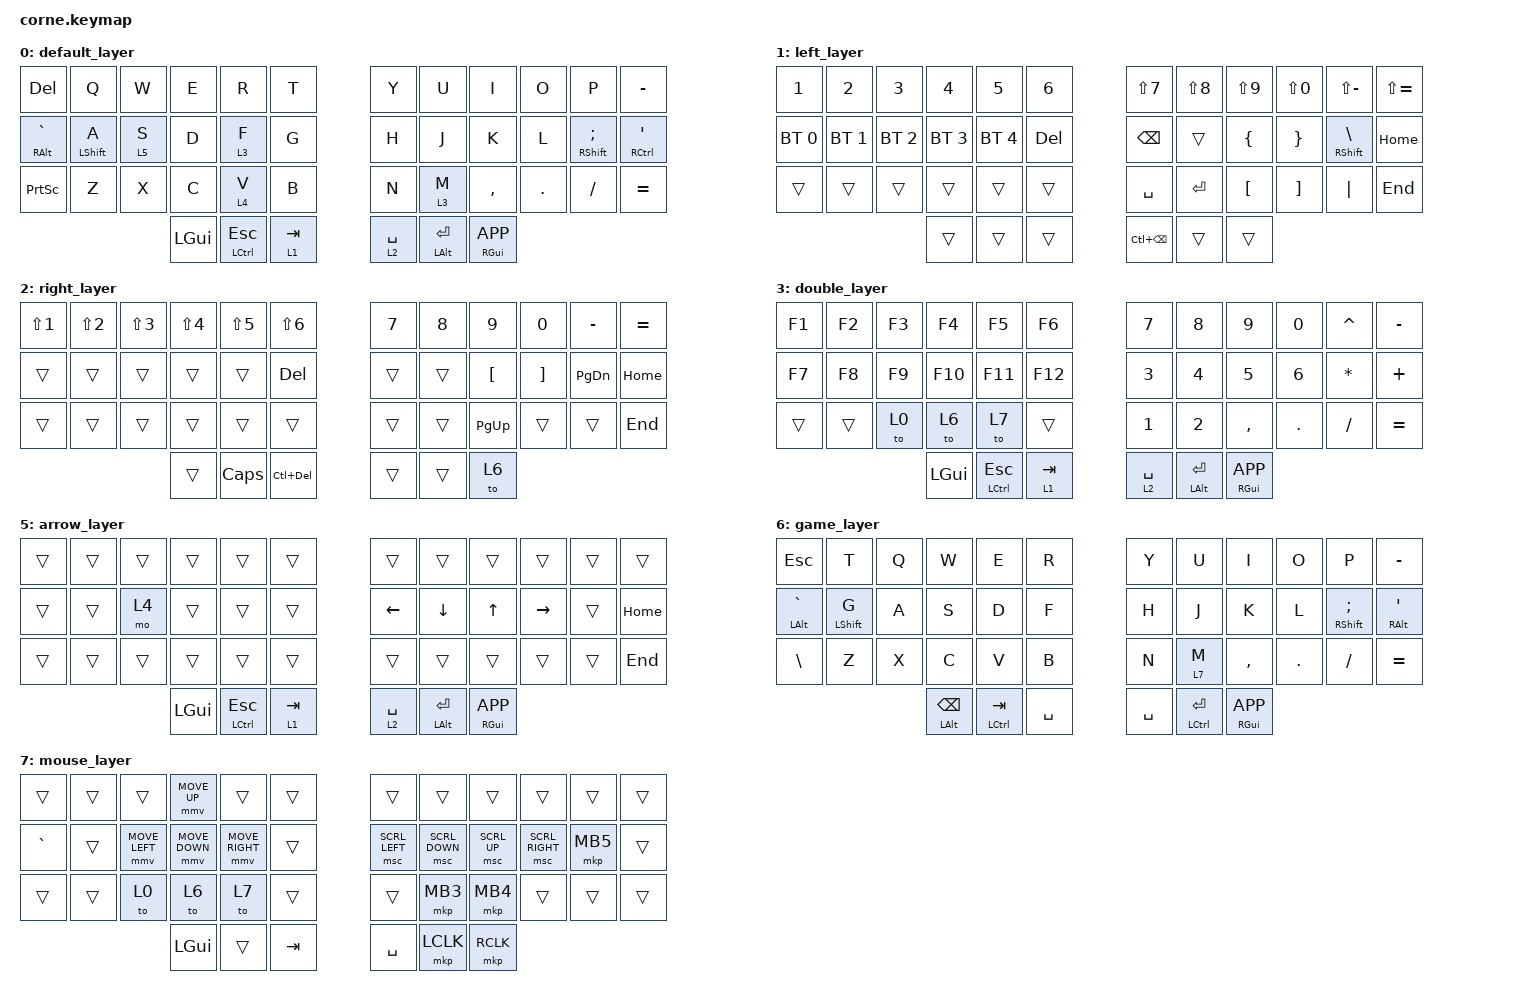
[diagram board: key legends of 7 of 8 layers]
/*
 * Copyright (c) 2020 The ZMK Contributors
 *
 * SPDX-License-Identifier: MIT
 */

#include <behaviors.dtsi>
#include <dt-bindings/zmk/keys.h>
#include <dt-bindings/zmk/bt.h>

// mouse
#include <dt-bindings/zmk/pointing.h>

&mt {
                        tapping-term-ms = <200>;
};

&lt {
            tapping-term-ms = <200>;    // <---[[moderate duration]]
            quick-tap-ms = <0>;
            flavor = "balanced";
};

/ {
    behaviors {
        hm: homerow_mods {
            compatible = "zmk,behavior-hold-tap";
            #binding-cells = <2>;
            tapping-term-ms = <150>;
            quick-tap-ms = <0>;
            flavor = "tap-preferred";
            bindings = <&kp>, <&kp>;
        };
    };
    behaviors {
        bhm: balanced_homerow_mods {
            compatible = "zmk,behavior-hold-tap";
            #binding-cells = <2>;
            tapping-term-ms = <200>;    // <---[[moderate duration]]
            quick-tap-ms = <0>;
            flavor = "balanced";
            bindings = <&kp>, <&kp>;
        };
    };

        keymap {
                compatible = "zmk,keymap";

                default_layer {
// -----------------------------------------------------------------------------------------
// |      |  Q  |  W  |  E  |  R  |  T  |   |  Y  |  U   |  I  |  O  |  P  |      |
// | CT/E |  A  |  S  |  D  |  F  |  G  |   |  H  |  J   |  K  |  L  |  ;  |  '   |
// | S/HM |  z  |  x  |  c  |  v  |  b  |   |  n  |  m   |  ,  |  .  |  /  | A/ED |
//                    | GUI | LWR | SPC |   | ENT | RSE  | ALT |
                        bindings = <
   &kp DEL       &kp Q        &kp W        &kp E              &kp R           &kp T         &kp Y &kp U  &kp I     &kp O     &kp P      &kp MINUS
   // &bhm LCTRL GRAVE     &bhm LSHFT A  &lt 5 S      &kp D            &lt 3 F         &kp G  &kp H &kp J  &kp K     &kp L     &bhm RSHFT SEMI &bhm RALT SQT
   &bhm RALT GRAVE     &bhm LSHFT A  &lt 5 S      &kp D            &lt 3 F         &kp G  &kp H &kp J  &kp K     &kp L     &bhm RSHFT SEMI &bhm RCTRL SQT
   &kp PSCRN   &kp Z   &kp X        &kp C              &lt 4 V           &kp B         &kp N &lt 3 M  &kp COMMA &kp DOT   &kp FSLH  &kp EQUAL
   // &kp LGUI   &lt 3 Z   &kp X        &kp C              &kp V           &kp B         &kp N &kp M  &kp COMMA &kp DOT   &lt 3 FSLH  &kp BSPC
                  // &kp LALT &lt 1 SPACE &lt 2 BSPC       &mt RSHFT RET     &lt 1 SPACE  &kp RALT
                  // &kp LGUI &mt LALT ESC &lt 1 TAB       &lt 2 SPACE   &mt LCTRL RET  &mt RGUI K_APP
                  &kp LGUI &mt LCTRL ESC &lt 1 TAB       &lt 2 SPACE   &mt LALT RET  &mt RGUI K_APP
                        >;
                };

                left_layer {
// -----------------------------------------------------------------------------------------
// |  TAB |  1  |  2  |  3  |  4  |  5  |   |  6  |  7  |  8  |  9  |  0  | BSPC |
// | BTCLR| BT1 | BT2 | BT3 | BT4 | BT5 |   | LFT | DWN |  UP | RGT |     |      |
                                                                        // | SHFT |     |     |     |     |     |   |     |     |     |     |     |      |
                                                                        //                    | GUI |     | SPC |   | ENT |     | ALT |
                        bindings = <
   // &kp N1       &kp N2       &kp N3       &kp N4       &kp N5       &kp N6  &kp AMPS     &kp STAR     &kp LPAR  &kp RPAR  &kp UNDER &kp PLUS 
   &kp N1       &kp N2       &kp N3       &kp N4       &kp N5       &kp N6  &kp LS(N7)     &kp LS(N8)     &kp LS(N9)  &kp LS(N0)  &kp LS(MINUS) &kp LS(EQUAL) 
   // &trans &kp N1       &kp N2       &kp N3       &kp N4       &kp N5       &kp CARET  &kp AMPS     &kp STAR     &kp LPAR  &kp RPAR  &trans
   // &kp N1       &kp N2       &kp N3       &kp N4       &kp N5       &kp N6  &kp N7     &kp N8     &kp N9 &kp N0 &kp MINUS &kp EQUAL  
   &bt BT_SEL 0  &bt BT_SEL 1  &bt BT_SEL 2   &bt BT_SEL 3    &bt BT_SEL 4  &kp DEL        &kp BSPC  &trans &kp LBRC  &kp RBRC  &bhm RSHFT BSLH   &kp HOME
   // &trans      &trans    &trans     &trans       &trans     &trans    &trans     &trans     &trans       &trans &kp LBKT  &kp RBKT 
   // &trans     &kp RET      &kp LEFT     &kp UP       &kp DOWN     &kp RIGHT    &trans     &kp PG_DN    &kp PG_UP    &kp LBKT &kp RBKT &kp MINUS
   &trans    &trans &trans &trans &trans &trans      &kp SPACE  &kp RET &kp LBKT &kp RBKT  &kp PIPE  &kp END
                                        &trans       &trans       &trans       &kp LC(BSPC)     &trans       &trans
                        >;
                };

                right_layer {
// -----------------------------------------------------------------------------------------
// |  TAB |  1  |  2  |  3  |  4  |  5  |   |  6  |  7  |  8  |  9  |  0  | BSPC |
// | BTCLR| BT1 | BT2 | BT3 | BT4 | BT5 |   | LFT | DWN |  UP | RGT |     |      |
// | SHFT |     |     |     |     |     |   |     |     |     |     |     |      |
//                    | GUI |     | SPC |   | ENT |     | ALT |
                        bindings = <
   // &kp EXCL     &kp AT       &kp HASH     &kp DOLLAR   &kp PERCENT       &kp CARET   &kp N7   &kp N8 &kp N9    &kp N0    &kp MINUS &kp EQUAL 
   &kp LS(N1)     &kp LS(N2)       &kp LS(N3)     &kp LS(N4)   &kp LS(N5)       &kp LS(N6)   &kp N7   &kp N8 &kp N9    &kp N0    &kp MINUS &kp EQUAL 
   // &trans &kp EXCL     &kp AT       &kp HASH     &kp DOLLAR   &kp PERCENT       &kp N6   &kp N7   &kp N8 &kp N9    &kp N0    &trans
   // &kp EXCL     &kp AT       &kp HASH     &kp DOLLAR   &kp PERCENT      &kp CARET  &kp AMPS     &kp STAR     &kp LPAR &kp RPAR &kp UNDER &kp PLUS  
   // &kp TILDE       &trans       &trans    &trans   &trans       &trans            &trans   &trans   &trans &trans  &kp LBRC &kp RBRC   
   &trans    &trans &trans &trans &trans &kp DEL    &trans    &trans &kp LBKT  &kp RBKT &kp PG_DN     &kp HOME
   // &trans     &trans       &trans       &trans       &trans       &trans            &trans   &trans   &trans &kp LBRC  &kp RBRC &kp UNDER
   &trans    &trans &trans &trans &trans &trans    &trans       &trans  &kp PG_UP   &trans &trans &kp END
                               &trans            &kp CAPS  &kp LC(DEL)      &trans   &trans   &to 6
                        >;
                };

                double_layer {
// -----------------------------------------------------------------------------------------
// |  TAB |  !  |  @  |  #  |  $  |  %  |   |  ^  |  &  |  *  |  (  |  )  | BSPC |
// | CTRL |     |     |     |     |     |   |  -  |  =  |  [  |  ]  |  \  |  `   |
// | SHFT |     |     |     |     |     |   |  _  |  +  |  {  |  }  | "|" |  ~   |
//                    | GUI |     | SPC |   | ENT |     | ALT |
                        bindings = <
   &kp F1   &kp F2  &kp F3   &kp F4  &kp F5   &kp F6        &kp N7  &kp N8  &kp N9 &kp N0  &kp CARET  &kp MINUS
   &kp F7   &kp F8  &kp F9   &kp F10 &kp F11  &kp F12     &kp N3 &kp N4  &kp N5  &kp N6  &kp ASTRK &kp PLUS
   &trans &trans &to 0 &to 6 &to 7 &trans       &kp N1  &kp N2   &kp COMMA  &kp DOT &kp SLASH   &kp EQUAL
                  // &kp LGUI &mt LALT ESC &lt 1 TAB       &lt 2 SPACE   &mt LCTRL RET  &mt RGUI K_APP
                  &kp LGUI &mt LCTRL ESC &lt 1 TAB       &lt 2 SPACE   &mt LALT RET  &mt RGUI K_APP
                           // &trans &trans  &trans      &trans    &trans  &trans
                        >;
                };

                control_layer {
// -----------------------------------------------------------------------------------------
// |  TAB |  !  |  @  |  #  |  $  |  %  |   |  ^  |  &  |  *  |  (  |  )  | BSPC |
// | CTRL |     |     |     |     |     |   |  -  |  =  |  [  |  ]  |  \  |  `   |
// | SHFT |     |     |     |     |     |   |  _  |  +  |  {  |  }  | "|" |  ~   |
//                    | GUI |     | SPC |   | ENT |     | ALT |
                        bindings = <
   &bt BT_CLR &trans   &trans  &trans   &trans  &trans   &trans &trans  &trans  &trans &kp C_PP    &trans
   &trans &trans   &trans  &trans  &trans  &trans   &kp C_PREV &kp C_VOL_DN &kp C_VOL_UP  &kp C_NEXT &trans   &trans
   &trans &trans   &trans  &trans   &trans  &trans   &trans &kp C_MUTE  &kp C_BRI_DN   &kp C_BRI_UP &trans  &trans &trans &trans
                           &trans &trans  &trans      &trans    &trans     &trans
                        >;
                };

                arrow_layer {
// -----------------------------------------------------------------------------------------
// |  TAB |  !  |  @  |  #  |  $  |  %  |   |  ^  |  &  |  *  |  (  |  )  | BSPC |
// | CTRL |     |     |     |     |     |   |  -  |  =  |  [  |  ]  |  \  |  `   |
// | SHFT |     |     |     |     |     |   |  _  |  +  |  {  |  }  | "|" |  ~   |
//                    | GUI |     | SPC |   | ENT |     | ALT |
                        bindings = <
   &trans &trans   &trans  &trans   &trans  &trans   &trans   &trans    &trans  &trans    &trans   &trans
   &trans &trans   &mo 4  &trans   &trans  &trans   &kp LEFT &kp DOWN  &kp UP  &kp RIGHT &trans &kp HOME
   &trans &trans   &trans &trans  &trans &trans   &trans   &trans   &trans  &trans    &trans   &kp END
                  // &kp LGUI &mt LALT ESC &lt 1 TAB       &lt 2 SPACE   &mt LCTRL RET  &mt RGUI K_APP
                  &kp LGUI &mt LCTRL ESC &lt 1 TAB       &lt 2 SPACE   &mt LALT RET  &mt RGUI K_APP
                           // &trans &trans  &trans      &trans    &trans     &trans
                        >;
                };

                game_layer {
// -----------------------------------------------------------------------------------------
// |      |  Q  |  W  |  E  |  R  |  T  |   |  Y  |  U   |  I  |  O  |  P  |      |
// | CT/E |  A  |  S  |  D  |  F  |  G  |   |  H  |  J   |  K  |  L  |  ;  |  '   |
// | S/HM |  z  |  x  |  c  |  v  |  b  |   |  n  |  m   |  ,  |  .  |  /  | A/ED |
//                    | GUI | LWR | SPC |   | ENT | RSE  | ALT |
                        bindings = <
   &kp ESC    &kp T       &kp Q               &kp W       &kp E              &kp R          &kp Y &kp U  &kp I     &kp O     &kp P      &kp MINUS
   &bhm LALT GRAVE  &bhm LSHFT G     &kp A               &kp S       &kp D              &kp F          &kp H &kp J  &kp K     &kp L     &bhm RSHFT SEMI &bhm RALT SQT
   &kp BSLH  &kp Z               &kp X       &kp C  &kp V  &kp B       &kp N &lt 7 M  &kp COMMA &kp DOT   &kp FSLH  &kp EQUAL
   // &kp LGUI   &lt 3 Z   &kp X        &kp C              &kp V           &kp B         &kp N &kp M  &kp COMMA &kp DOT   &lt 3 FSLH  &kp BSPC
                  // &kp LALT &lt 1 SPACE &lt 2 BSPC       &mt RSHFT RET     &lt 1 SPACE  &kp RALT
                  &mt LALT BSPC &mt LCTRL TAB  &kp SPACE       &kp SPACE   &mt LCTRL RET  &mt RGUI K_APP
                        >;
                };

                mouse_layer {
// -----------------------------------------------------------------------------------------
// |  TAB |  !  |  @  |  #  |  $  |  %  |   |  ^  |  &  |  *  |  (  |  )  | BSPC |
// | CTRL |     |     |     |     |     |   |  -  |  =  |  [  |  ]  |  \  |  `   |
// | SHFT |     |     |     |     |     |   |  _  |  +  |  {  |  }  | "|" |  ~   |
//                    | GUI |     | SPC |   | ENT |     | ALT |
                        bindings = <
   &trans &trans   &trans      &mmv MOVE_UP   &trans  &trans   &trans   &trans    &trans  &trans    &trans   &trans
   &kp GRAVE &trans   &mmv MOVE_LEFT  &mmv MOVE_DOWN   &mmv MOVE_RIGHT  &trans   &msc SCRL_LEFT &msc SCRL_DOWN  &msc SCRL_UP  &msc SCRL_RIGHT &mkp MB5  &trans
   &trans &trans  &to 0 &to 6  &to 7 &trans  &trans   &mkp MB3   &mkp MB4  &trans    &trans   &trans
                  // &kp LGUI &mt LALT ESC &lt 1 TAB       &lt 2 SPACE   &mt LCTRL RET  &mt RGUI K_APP
                  // &kp LGUI &mt LCTRL ESC &mkp RCLK       &mkp LCLK   &mt LALT RET  &mt RGUI K_APP
                  &kp LGUI &trans &kp TAB       &kp SPACE   &mkp LCLK  &mkp RCLK
                           // &trans &trans  &trans      &trans    &trans     &trans
                        >;
                };

        };
};
